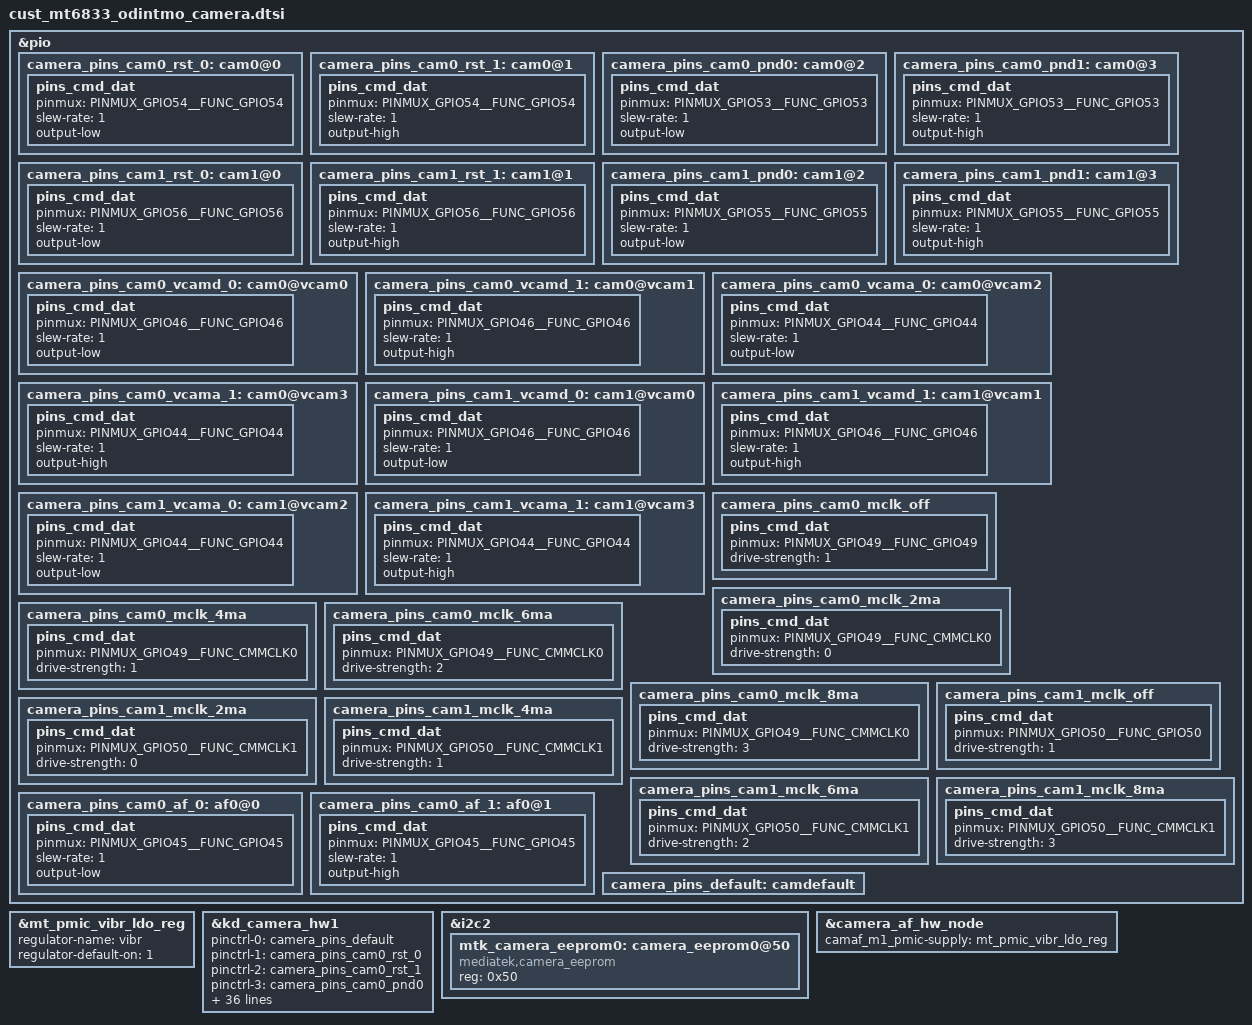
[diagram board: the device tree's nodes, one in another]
/* CAMERA GPIO standardization */
&pio {
	camera_pins_cam0_rst_0: cam0@0 {
		pins_cmd_dat {
			pinmux = <PINMUX_GPIO54__FUNC_GPIO54>;
			slew-rate = <1>;
			output-low;
		};
	};
	camera_pins_cam0_rst_1: cam0@1 {
		pins_cmd_dat {
			pinmux = <PINMUX_GPIO54__FUNC_GPIO54>;
			slew-rate = <1>;
			output-high;
		};
	};
	camera_pins_cam0_pnd0: cam0@2 {
		pins_cmd_dat {
			pinmux  = <PINMUX_GPIO53__FUNC_GPIO53>;
			slew-rate = <1>;
			output-low;
		};
	};
	camera_pins_cam0_pnd1: cam0@3 {
		pins_cmd_dat {
			pinmux  = <PINMUX_GPIO53__FUNC_GPIO53>;
			slew-rate = <1>;
			output-high;
		};
	};

	camera_pins_cam1_rst_0: cam1@0 {
		pins_cmd_dat {
			pinmux = <PINMUX_GPIO56__FUNC_GPIO56>;
			slew-rate = <1>;
			output-low;
		};
	};
	camera_pins_cam1_rst_1: cam1@1 {
		pins_cmd_dat {
			pinmux = <PINMUX_GPIO56__FUNC_GPIO56>;
			slew-rate = <1>;
			output-high;
		};
	};

	camera_pins_cam1_pnd0: cam1@2 {
		pins_cmd_dat {
			pinmux  = <PINMUX_GPIO55__FUNC_GPIO55>;
			slew-rate = <1>;
			output-low;
		};
	};
	camera_pins_cam1_pnd1: cam1@3 {
		pins_cmd_dat {
			pinmux  = <PINMUX_GPIO55__FUNC_GPIO55>;
			slew-rate = <1>;
			output-high;
		};
	};

	camera_pins_cam0_vcamd_0: cam0@vcam0 {
		pins_cmd_dat {
			pinmux = <PINMUX_GPIO46__FUNC_GPIO46>;//48
			slew-rate = <1>;
			output-low;
		};
	};
	camera_pins_cam0_vcamd_1: cam0@vcam1 {
		pins_cmd_dat {
			pinmux = <PINMUX_GPIO46__FUNC_GPIO46>;//48
			slew-rate = <1>;
			output-high;
		};
	};
	camera_pins_cam0_vcama_0: cam0@vcam2 {
		pins_cmd_dat {
			pinmux = <PINMUX_GPIO44__FUNC_GPIO44>;//94
			slew-rate = <1>;
			output-low;
		};
	};
	camera_pins_cam0_vcama_1: cam0@vcam3 {
		pins_cmd_dat {
			pinmux = <PINMUX_GPIO44__FUNC_GPIO44>;//94
			slew-rate = <1>;
			output-high;
		};
	};

	camera_pins_cam1_vcamd_0: cam1@vcam0 {
		pins_cmd_dat {
			pinmux = <PINMUX_GPIO46__FUNC_GPIO46>;//45
			slew-rate = <1>;
			output-low;
		};
	};
	camera_pins_cam1_vcamd_1: cam1@vcam1 {
		pins_cmd_dat {
			pinmux = <PINMUX_GPIO46__FUNC_GPIO46>;//45
			slew-rate = <1>;
			output-high;
		};
	};
	camera_pins_cam1_vcama_0: cam1@vcam2 {
		pins_cmd_dat {
			pinmux = <PINMUX_GPIO44__FUNC_GPIO44>;//18
			slew-rate = <1>;
			output-low;
		};
	};
	camera_pins_cam1_vcama_1: cam1@vcam3 {
		pins_cmd_dat {
			pinmux = <PINMUX_GPIO44__FUNC_GPIO44>;//18
			slew-rate = <1>;
			output-high;
		};
	};

	camera_pins_cam0_mclk_off: camera_pins_cam0_mclk_off {
		pins_cmd_dat {
			pinmux = <PINMUX_GPIO49__FUNC_GPIO49>;
			drive-strength = <1>;
		};
	};
	camera_pins_cam0_mclk_2ma: camera_pins_cam0_mclk_2ma {
		pins_cmd_dat {
			pinmux = <PINMUX_GPIO49__FUNC_CMMCLK0>;
			drive-strength = <0>;
		};
	};
	camera_pins_cam0_mclk_4ma: camera_pins_cam0_mclk_4ma {
		pins_cmd_dat {
			pinmux = <PINMUX_GPIO49__FUNC_CMMCLK0>;
			drive-strength = <1>;
		};
	};
	camera_pins_cam0_mclk_6ma: camera_pins_cam0_mclk_6ma {
		pins_cmd_dat {
			pinmux = <PINMUX_GPIO49__FUNC_CMMCLK0>;
			drive-strength = <2>;
		};
	};
	camera_pins_cam0_mclk_8ma: camera_pins_cam0_mclk_8ma {
		pins_cmd_dat {
			pinmux = <PINMUX_GPIO49__FUNC_CMMCLK0>;
			drive-strength = <3>;
		};
	};
	camera_pins_cam1_mclk_off: camera_pins_cam1_mclk_off {
		pins_cmd_dat {
			pinmux = <PINMUX_GPIO50__FUNC_GPIO50>;
			drive-strength = <1>;
		};
	};
	camera_pins_cam1_mclk_2ma: camera_pins_cam1_mclk_2ma {
		pins_cmd_dat {
			pinmux = <PINMUX_GPIO50__FUNC_CMMCLK1>;
			drive-strength = <0>;
		};
	};
	camera_pins_cam1_mclk_4ma: camera_pins_cam1_mclk_4ma {
		pins_cmd_dat {
			pinmux = <PINMUX_GPIO50__FUNC_CMMCLK1>;
			drive-strength = <1>;
		};
	};
	camera_pins_cam1_mclk_6ma: camera_pins_cam1_mclk_6ma {
		pins_cmd_dat {
			pinmux = <PINMUX_GPIO50__FUNC_CMMCLK1>;
			drive-strength = <2>;
		};
	};
	camera_pins_cam1_mclk_8ma: camera_pins_cam1_mclk_8ma {
		pins_cmd_dat {
			pinmux = <PINMUX_GPIO50__FUNC_CMMCLK1>;
			drive-strength = <3>;
		};
	};
//af start
	camera_pins_cam0_af_0: af0@0 {
		pins_cmd_dat {
			pinmux = <PINMUX_GPIO45__FUNC_GPIO45>;
			slew-rate = <1>;
			output-low;
		};
	};
	camera_pins_cam0_af_1: af0@1 {
		pins_cmd_dat {
			pinmux = <PINMUX_GPIO45__FUNC_GPIO45>;
			slew-rate = <1>;
			output-high;
		};
	};
//af end

	camera_pins_default: camdefault {
	};
};
&mt_pmic_vibr_ldo_reg {
        regulator-name = "vibr";
        regulator-default-on = <1>; /* 0:skip, 1: off, 2:on */
        status = "okay";
};

&kd_camera_hw1 {
	pinctrl-names = "default",
			"cam0_rst0", "cam0_rst1",
			"cam0_pnd0", "cam0_pnd1",
			"cam1_rst0", "cam1_rst1",
                        "cam1_pnd0", "cam1_pnd1", 
			"cam0_ldo_vcamd_0", "cam0_ldo_vcamd_1",
			"cam0_ldo_vcama_0", "cam0_ldo_vcama_1",
			"cam1_ldo_vcamd_0", "cam1_ldo_vcamd_1",
			"cam1_ldo_vcama_0", "cam1_ldo_vcama_1",
			"cam0_mclk_off",
			"cam0_mclk_2mA", "cam0_mclk_4mA",
			"cam0_mclk_6mA", "cam0_mclk_8mA",
			"cam1_mclk_off",
			"cam1_mclk_2mA", "cam1_mclk_4mA",
			"cam1_mclk_6mA", "cam1_mclk_8mA",
			"cam0_vcamaf1", "cam0_vcamaf0";
	pinctrl-0 = <&camera_pins_default>;
	pinctrl-1 = <&camera_pins_cam0_rst_0>;
	pinctrl-2 = <&camera_pins_cam0_rst_1>;
	pinctrl-3 = <&camera_pins_cam0_pnd0>;
	pinctrl-4 = <&camera_pins_cam0_pnd1>;
	pinctrl-5 = <&camera_pins_cam1_rst_0>;
	pinctrl-6 = <&camera_pins_cam1_rst_1>;
        pinctrl-7 = <&camera_pins_cam1_pnd0>;
	pinctrl-8 = <&camera_pins_cam1_pnd1>;
	pinctrl-9 = <&camera_pins_cam0_vcamd_0>;
	pinctrl-10 = <&camera_pins_cam0_vcamd_1>;
	pinctrl-11 = <&camera_pins_cam0_vcama_0>;
	pinctrl-12 = <&camera_pins_cam0_vcama_1>;
	pinctrl-13 = <&camera_pins_cam1_vcamd_0>;
	pinctrl-14 = <&camera_pins_cam1_vcamd_1>;
	pinctrl-15 = <&camera_pins_cam1_vcama_0>;
	pinctrl-16 = <&camera_pins_cam1_vcama_1>;
	pinctrl-17 = <&camera_pins_cam0_mclk_off>;
	pinctrl-18 = <&camera_pins_cam0_mclk_2ma>;
	pinctrl-19 = <&camera_pins_cam0_mclk_4ma>;
	pinctrl-20 = <&camera_pins_cam0_mclk_6ma>;
	pinctrl-21 = <&camera_pins_cam0_mclk_8ma>;
	pinctrl-22 = <&camera_pins_cam1_mclk_off>;
	pinctrl-23 = <&camera_pins_cam1_mclk_2ma>;
	pinctrl-24 = <&camera_pins_cam1_mclk_4ma>;
	pinctrl-25 = <&camera_pins_cam1_mclk_6ma>;
	pinctrl-26 = <&camera_pins_cam1_mclk_8ma>;
	pinctrl-27 = <&camera_pins_cam0_af_1>;
	pinctrl-28 = <&camera_pins_cam0_af_0>;


	cam0_vcama-supply = <&mt_pmic_vfp_ldo_reg>;
	cam0_vcamio-supply = <&mt_pmic_vcamio_ldo_reg>;
	cam1_vcama-supply = <&mt_pmic_vfp_ldo_reg>;
	cam1_vcamio-supply = <&mt_pmic_vcamio_ldo_reg>;


	cam0_enable_sensor = "gc08a3odin5gtmo_mipi_raw hi846odin5g_mipi_raw";
	cam1_enable_sensor = "gc5035odin5gtsp_mipi_raw gc5035odin5gui_mipi_raw";
	cam2_enable_sensor = "";
	cam4_enable_sensor = "";
	cam6_enable_sensor = "";

	status = "okay";
};
/* CAMERA GPIO end */

/* CAMERA EEPROM */
&i2c2 {
	mtk_camera_eeprom0:camera_eeprom0@50 {
		compatible = "mediatek,camera_eeprom";
		reg = <0x50>;
		status = "okay";
	};
};
/* CAMERA AF */
&camera_af_hw_node {
	camaf_m1_pmic-supply = <&mt_pmic_vibr_ldo_reg>;
	//camaf_m2_pmic-supply = <&mt_pmic_vcamio_ldo_reg>;
	//camaf_m3_pmic-supply = <&mt_pmic_vcamio_ldo_reg>;
	status = "okay";
};
/* CAMERA AF end */
/* CAMERA EEPROM end */

